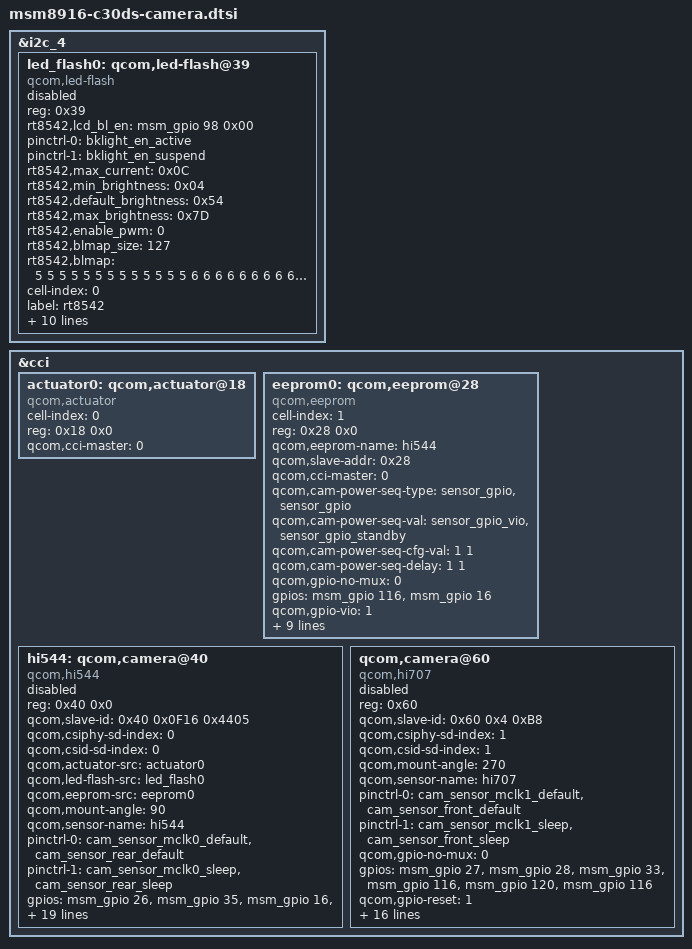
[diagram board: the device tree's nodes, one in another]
/*
 * Copyright (c) 2013, The Linux Foundation. All rights reserved.
 *
 * This program is free software; you can redistribute it and/or modify
 * it under the terms of the GNU General Public License version 2 and
 * only version 2 as published by the Free Software Foundation.
 *
 * This program is distributed in the hope that it will be useful,
 * but WITHOUT ANY WARRANTY; without even the implied warranty of
 * MERCHANTABILITY or FITNESS FOR A PARTICULAR PURPOSE.  See the
 * GNU General Public License for more details.
 */

&i2c_4 {
	led_flash0: qcom,led-flash@39 {
		compatible                = "qcom,led-flash";
		status                    = "disabled";
		reg                       = <0x39>;
		rt8542,lcd_bl_en = <&msm_gpio 98 0x00>;
		pinctrl-names = "default", "sleep";
		pinctrl-0 = <&bklight_en_active>;
		pinctrl-1 = <&bklight_en_suspend>;

		//TODO: CHECK if we can use this pins.
		//qcom,enable_pinctrl;
		//pinctrl-names             = "cam_flash_default",
		//							  "cam_flash_suspend";
		//pinctrl-0                 = <&cam_sensor_flash_default>;
		//pinctrl-1                 = <&cam_sensor_flash_sleep>;

		rt8542,max_current        = <0x0C>;
		rt8542,min_brightness     = <0x04>;
		rt8542,default_brightness = <0x54>;
		rt8542,max_brightness     = <0x7D>;
		rt8542,enable_pwm         = <0>;
		rt8542,blmap_size         = <127>;
		rt8542,blmap = <
			5 5 5 5 5 5 5 5 5 5 			//9
			5 5 5 6 6 6 6 6 6 6 			//19
			6 6 6 6 6 6 7 7 7 7 			//29
			7 7 7 8 8 8 8 9 9 9 			//39
			10 10 10 11 11 11 12 12 12 12 	//49
			13 13 14 14 14 14 15 15 15 16 	//59
			17 18 19 20 20 21 22 23 23 24	//69
			24 25 25 25 26 26 26 27 27 27 	//79
			27 28 29 30 31 32 33 34 35 36 	//89
			37 38 38 39 40 41 42 43 44 45   //99
			46 47 48 49 50 52 53 54 55 56	//109
			57 58 59 60 61 63 64 65 67 68	//119
			70 71 73 75 77 79 80>;

		cell-index = <0>;
		label                   = "rt8542";
		qcom,flash-name         = "rt8542";
		qcom,slave-id           = <0x39 0x00 0x0011>;
		qcom,flash-type         = <1>;              // LED_FLASH
		qcom,gpio-no-mux        = <0>;
		gpios                   = <&msm_gpio 31 0>; // FLASH_STROBE_TRIG, GPIO 31
		qcom,gpio-flash-en      = <0>;
		qcom,gpio-req-tbl-num   = <0>;
		qcom,gpio-req-tbl-flags = <0>;
		qcom,gpio-req-tbl-label = "FLASH_EN";
		qcom,cci-master = <0>;
	};
};
&cci {

	actuator0: qcom,actuator@18 {
		cell-index = <0>;	//Use Af_main_0 of dw9716 with HI544
		reg = <0x18 0x0>;
		compatible = "qcom,actuator";
		qcom,cci-master = <0>;
	};

	eeprom0: qcom,eeprom@28 {           //EEPROM READ
		cell-index       = <1>;
		reg              = <0x28 0x0>;
		qcom,eeprom-name = "hi544";
		compatible       = "qcom,eeprom";
		qcom,slave-addr  = <0x28>;
		qcom,cci-master  = <0>;

		qcom,cam-power-seq-type    = "sensor_gpio","sensor_gpio";
		qcom,cam-power-seq-val     = "sensor_gpio_vio","sensor_gpio_standby";
		qcom,cam-power-seq-cfg-val = <1 1>;
		qcom,cam-power-seq-delay   = <1 1>;
		qcom,gpio-no-mux           = <0>;
		
		gpios = <&msm_gpio 116 0>,   //CAM_IOVDD_1.8V,     LDO3_EN=GPIO 116
		        <&msm_gpio 16 0>;    //MAIN_CAM0_VCM_PWDN, GPIO 16
		        
		qcom,gpio-vio           = <1>;
		qcom,gpio-standby       = <0>;        //CAM_STANDBY
		qcom,gpio-req-tbl-num   = <0 1>;
		qcom,gpio-req-tbl-flags = <0 0>;
		qcom,gpio-req-tbl-label = "MAIN_VIO_EN",
		                          "CAM_STANDBY";
		qcom,num-blocks = <1>;
		qcom,page0 = <0 0x0 1 0x0 1 20>;    // valid size, addr, addr_t, data, data_t, delay
		qcom,poll0 = <0 0x0 1 0x0 1 20>;
		qcom,mem0  = <0x382 0x0000 2 0 1 0>; // EEPROM READ
	};

	hi544:qcom,camera@40 {
		compatible           = "qcom,hi544";
		reg                  = <0x40 0x0>;
		qcom,slave-id        = <0x40 0x0F16 0x4405>;
		qcom,csiphy-sd-index = <0>;
		qcom,csid-sd-index   = <0>;
		qcom,actuator-src    = <&actuator0>;
		qcom,led-flash-src   = <&led_flash0>;
		qcom,eeprom-src      = <&eeprom0>;
		qcom,mount-angle     = <90>;
		qcom,sensor-name     = "hi544";

		pinctrl-names = "cam_default", "cam_suspend";
		pinctrl-0 = <&cam_sensor_mclk0_default &cam_sensor_rear_default>;
		pinctrl-1 = <&cam_sensor_mclk0_sleep &cam_sensor_rear_sleep>;

		gpios = <&msm_gpio 26 0>,    //MAIN_CAM0_MCLK
		        <&msm_gpio 35 0>,    //MAIN_CAM0_RESET_N --> StandBY
		        <&msm_gpio 16 0>,    //MAIN_CAM0_VCM_PWDN
		        <&msm_gpio 121 0>,   //CAM_DVDD_1.2V,  LDO2_EN=GPIO 121 //<&msm_gpio 116 0>,   //CAM_DVDD_1.8V,  LDO3_EN=GPIO 116
		        <&msm_gpio 120 0>,   //CAM_AVDD_2.8V,  LDO1_EN=GPIO 120
		        <&msm_gpio 116 0>;   //CAM_IOVDD_1.8V, LDO3_EN=GPIO 116

		qcom,gpio-no-mux    = <0>;
		qcom,gpio-standby   = <1>; //gpio-reset
		qcom,gpio-af-pwdm   = <2>;
		qcom,gpio-vdig      = <3>;
		qcom,gpio-vana      = <4>;
		qcom,gpio-vio       = <5>;

		qcom,gpio-req-tbl-num	= <0 1 2 3 4 5>;
		qcom,gpio-req-tbl-flags	= <1 0 0 0 0 0>;
		qcom,gpio-req-tbl-label	= "CAMIF_MCLK",
		                          "CAM_STANDBY",
		                          "MAIN_AF_PWDN",
		                          "MAIN_VDIG_EN",
		                          "MAIN_VANA_EN",
		                          "MAIN_VIO_EN";

		qcom,csi-lane-assign = <0x4320>;
		qcom,csi-lane-mask   = <0x07>;
		qcom,sensor-position = <0>;
		qcom,sensor-mode     = <1>;
		qcom,cci-master      = <0>;

		status = "disabled";
		clocks = <&clock_gcc clk_mclk0_clk_src>,
				 <&clock_gcc clk_gcc_camss_mclk0_clk>;
		clock-names = "cam_src_clk", "cam_clk";
	};

	qcom,camera@60 {
		compatible           = "qcom,hi707";
		reg                  = <0x60>;
		qcom,slave-id        = <0x60 0x4 0xB8>;
		qcom,csiphy-sd-index = <1>;
		qcom,csid-sd-index   = <1>; //<0>
		qcom,mount-angle     = <270>;
		qcom,sensor-name     = "hi707";

		pinctrl-names = "cam_default", "cam_suspend";
		pinctrl-0 = <&cam_sensor_mclk1_default &cam_sensor_front_default>;
		pinctrl-1 = <&cam_sensor_mclk1_sleep &cam_sensor_front_sleep>;

		qcom,gpio-no-mux = <0>;
		gpios = <&msm_gpio 27  0>,    //VT_CAM_MCLK,    GPIO 27
		        <&msm_gpio 28  0>,    //VT_CAM_RESET_N, GPIO 28
		        <&msm_gpio 33  0>,    //VT_CAM_PWDN,    GPIO 33
		        <&msm_gpio 116 0>,    //DVDD,  1V8_CAM_LDO,    LDO3_EN=GPIO 116
		        <&msm_gpio 120 0>,    //AVDD,  2V8_CAM_AVDD,   LDO1_EN=GPIO 120
		        <&msm_gpio 116 0>;    //IOVDD, 1V8_CAM_LDO,    LDO3_EN=GPIO 116

		qcom,gpio-reset   = <1>;
		qcom,gpio-standby = <2>;
		qcom,gpio-vdig    = <3>;		// 1V8_CAM_LDO
		qcom,gpio-vana    = <4>;		// 2V8_CAM_AVDD
		qcom,gpio-vio     = <5>;		// 1V8_CAM_LDO

		qcom,gpio-req-tbl-num   = <0 1 2 3 4>;
		qcom,gpio-req-tbl-flags = <1 0 0 0 0>;
		qcom,gpio-req-tbl-label = "CAMIF_MCLK2",
		                          "CAM_RESET2",
		                          "CAM_STANDBY2",
		                          "MAIN_VDIG_EN2",
		                          "MAIN_VANA_EN2";
		                          
		qcom,csi-lane-assign    = <0x4320>;
		qcom,csi-lane-mask      = <0x3>;
		qcom,sensor-position    = <1>;
		qcom,sensor-mode        = <1>;
		qcom,cci-master         = <0>;

		status = "disabled";
		clocks = <&clock_gcc clk_mclk1_clk_src>,
		         <&clock_gcc clk_gcc_camss_mclk1_clk>;
		clock-names = "cam_src_clk", "cam_clk";
	};

};
